# AM13E230x register map
Vendor: Texas Instruments; File version: Revised: 2025-12-26 17:30:06
CPU: CM33 r0p0, little endian, MPU, FPU, 4 interrupt priority bits
Registers are 32-bit, read-write, reset 0x0 unless marked. A register's access mark holds for its fields unless they carry their own. Offsets are from the block's base; [hi:lo] are bit positions; {n}, {i} and the like mark numbered series; 'fields as' and 'values as' point back to an identical list.

## EPI0 — External peripheral interface
Base 0x4001A000
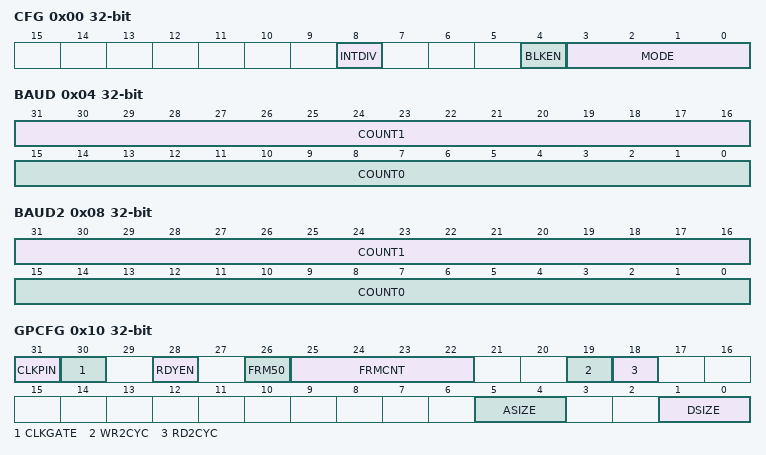
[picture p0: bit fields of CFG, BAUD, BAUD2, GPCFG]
0x00 CFG — EPI Configuration
  [8] INTDIV — Integer Clock Divider Enable
    0=FORMULA (EPIBAUD register values create formula clock divide.); 1=INTEGER (EPIBAUD register values create integer clock divide.)
  [4] BLKEN — Block Enable
    0=DISABLE (The EPI controller is disabled.); 1=ENABLE (The EPI controller is enabled.)
  [3:0] MODE — Mode Select
    0=GP (General Purpose. General-Purpose mode. Control, address, and data pins are configured using the EPIGPCFG and EPIGPCFG2 registers.); 1=SDRAM (SDRAM. Supports SDR SDRAM. Control, address, and data pins are configured using the EPISDRAMCFG register.); 2=HB8 (8-Bit Host-Bus (HB8). Host-bus 8-bit interface (also known as the MCU interface). Control, address, and data pins are configured using the EPIHB8CFG and EPIHB8CFG2 registers.); 3=HB16 (16-Bit Host-Bus (HB16). Host-bus 16-bit interface (standard SRAM). Control, address, and data pins are configured using the EPIHB16CFG and EPIHB16CFG2 registers.)
0x04 BAUD — EPI Main Baud Rate
  [31:16] COUNT1 — Baud Rate Counter 1
  [15:0] COUNT0 — Baud Rate Counter 0
0x08 BAUD2 — EPI Main Baud Rate
  [31:16] COUNT1 — CS3n Baud Rate Counter 1
  [15:0] COUNT0 — CS2n Baud Rate Counter 0
0x10 GPCFG — EPI General-Purpose Configuration
  [31] CLKPIN — Clock Pin
    0=DISABLE (No clock output.); 1=ENABLE (EPI0S31 functions as the EPI clock output.)
  [30] CLKGATE — Clock Gated
    0=FREE_RUN (The EPI clock is free running.); 1=FORCE_LOW (The EPI clock is output only when there is data to write or read (current transaction); otherwise the EPI clock is held low.)
  [28] RDYEN — Ready Enable
    0=NOT_USED (The external peripheral does not drive an iRDY signal and is assumed to be ready always.); 1=ENABLE (The external peripheral drives an iRDY signal into pin EPI0S27.)
  [26] FRM50 — 50/50 Frame
    0=GPCFG_FRAME_PULSE (The FRAME signal is output as a single pulse, and then held low for the count.); 1=GPCFG_FRAME_50_50 (The FRAME signal is output as 50/50 duty cycle using count (see FRMCNT).)
  [25:22] FRMCNT — Frame Count
  [19] WR2CYC — 2-Cycle Writes
    0=ONE (Data is output on the same EPI clock cycle as the address.); 1=TWO (Writes are two EPI clock cycles long, with address on one EPI clock cycle (with the WR strobe asserted) and data written on the following EPI clock cycle (with WR strobe de-asserted). The next address (if any) is in the cycle following.)
  [18] RD2CYC — 2-Cycle Reads
    0=ONE (Data is captured on the EPI clock cycle with READ strobe asserted.); 1=TWO (Reads are two EPI clock cycles, with address on one EPI clock cycle (with the RD strobe asserted) and data captured on the following EPI clock cycle (with the RD strobe de-asserted). The next address (if any) is in the cycle following.)
  [5:4] ASIZE — Address Bus Size
    0=GPCFG_ADDR_SIZE_NONE (No address); 1=GPCFG_ADDR_SIZE_4 (Up to 4 bits wide.); 2=GPCFG_ADDR_SIZE_12 (Up to 12 bits wide. This size cannot be used with 24-bit data.); 3=GPCFG_ADDR_SIZE_20 (Up to 20 bits wide. This size cannot be used with data sizes other than 8.)
  [1:0] DSIZE — Size of Data Bus
    0=GPCFG_BUS_SIZE_8 (8 bits wide (EPI0S0 to EPI0S7)); 1=GPCFG_BUS_SIZE_16 (16 bits wide (EPI0S0 to EPI0S15)); 2=GPCFG_BUS_SIZE_24 (24 bits wide (EPI0S0 to EPI0S23)); 3=GPCFG_BUS_SIZE_32 (32 bits wide (EPI0S0 to EPI0S31)This size may not be used with an EPI clock. This value is normally used for acquisition input and actuator control as well as other general-purpose uses that require 32 bits per direction.)
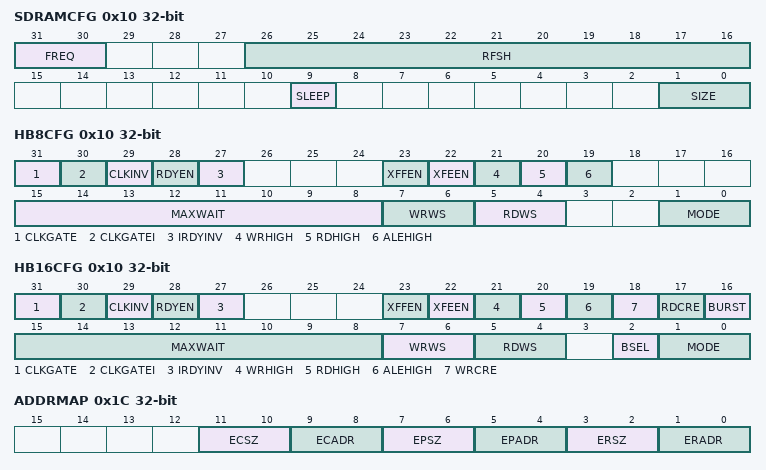
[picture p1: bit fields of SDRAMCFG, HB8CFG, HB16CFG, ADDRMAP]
0x10 SDRAMCFG (alternate view of GPCFG) — EPI SDRAM Configuration
  [31:30] FREQ — EPI Frequency Range.
    0=SDRAMCFG_0_TO_15_MHZ (0 to 15 MHz); 1=SDRAMCFG_15_TO_30_MHZ (15 to 30 MHz); 2=SDRAMCFG_30_TO_50_MHZ (30 to 50 MHz); 3=SDRAMCFG_50_TO_100_MHZ (50 to 100 MHz)
  [26:16] RFSH — Refresh Counter
  [9] SLEEP — Sleep Mode
    0=NONE (No effect.); 1=ON (The SDRAM is put into low power state, but is self-refreshed.)
  [1:0] SIZE — Size of SDRAM
    0=SDRAMCFG_SIZE_64MBITS (64 megabits (8MB)); 1=SDRAMCFG_SIZE_128MBITS (128 megabits (16MB)); 2=SDRAMCFG_SIZE_256MBITS (256 megabits (32MB)); 3=SDRAMCFG_SIZE_512MBITS (512 megabits (64MB))
0x10 HB8CFG (alternate view of GPCFG) — EPI Host-Bus 8 Configuration
  [31] CLKGATE — Clock Gated
    0=FREE_RUN (The EPI clock is free running.); 1=FORCE_LOW (The EPI clock is held low.)
  [30] CLKGATEI — Clock Gated when Idle
    values as GPCFG.CLKGATE
  [29] CLKINV — Invert Output Clock Enable
    0=NORMAL (No effect.); 1=INVERT (Invert EPI clock to ensure the rising edge is centered for outbound signal's setup and hold. Inbound signal is captured on rising edge EPI clock.)
  [28] RDYEN — Input Ready Enable
    0=DISABLE (No effect.); 1=ENABLE (An external ready can be used to control the continuation of the current access. If this bit is set and the iRDY signal (EPIS032) is low, the current access is stalled.)
  [27] IRDYINV — Input Ready Invert
    0=NORMAL (No effect.); 1=INVERT (Invert the polarity of incoming external ready (iRDY signal). If this bit is set and the iRDY signal (EPIS032) is high the current access is stalled.)
  [23] XFFEN — External FIFO FULL Enable
    0=MONITOR_OFF (No effect.); 1=MONITOR (An external FIFO full signal can be used to control write cycles. If this bit is set and the FFULL full signal is high, XFIFO writes are stalled.)
  [22] XFEEN — External FIFO EMPTY Enable
    0=MONITOR_OFF (No effect.); 1=MONITOR (An external FIFO empty signal can be used to control read cycles. If this bit is set and the FEMPTY signal is high, XFIFO reads are stalled.)
  [21] WRHIGH — WRITE Strobe Polarity
    0=LOW (The WRITE strobe for CS0n is WRn (active Low).); 1=HIGH (The WRITE strobe for CS0n is WR (active High).)
  [20] RDHIGH — READ Strobe Polarity
    0=LOW (The READ strobe for CS0n is RDn (active Low).); 1=HIGH (The READ strobe for CS0n is RD (active High).)
  [19] ALEHIGH — ALE Strobe Polarity
    0=LOW (The address latch strobe for CS0n accesses is ALEn (active Low).); 1=HIGH (The address latch strobe for CS0n accesses is ALE (active High).)
  [15:8] MAXWAIT — Maximum Wait
  [7:6] WRWS — Write Wait States
    0=WRN2 (Active WRn is 2 EPI clocks.); 1=WRN4 (Active WRn is 4 EPI clocks.); 2=WRN6 (Active WRn is 6 EPI clocks.); 3=WRN8 (Active WRn is 8 EPI clocks.)
  [5:4] RDWS — Read Wait States
    0=RDN2 (Active RDn is 2 EPI clocks.); 1=RDN4 (Active RDn is 4 EPI clocks.); 2=RDN6 (Active RDn is 6 EPI clocks.); 3=RDN8 (Active RDn is 8 EPI clocks.)
  [1:0] MODE — Host Bus Sub-Mode
    0=ADMUX (ADMUX - AD[7:0]. Data and Address are muxed.); 1=ADNONMUX (ADNONMUX - D[7:0]. Data and address are separate.); 2=CONT_READ (Continuous Read - D[7:0]. This mode is the same as ADNONMUX, but uses address switch for multiple reads instead of OEn strobing.); 3=XFIFO (XFIFO - D[7:0]. This mode adds XFIFO controls with sense of XFIFO full and XFIFO empty. This mode uses no address or ALE. The XFIFO can only be used in asynchronous mode.)
0x10 HB16CFG (alternate view of GPCFG) — EPI Host-Bus 16 Configuration
  [31] CLKGATE — Clock Gated
    values as HB8CFG.CLKGATE
  [30] CLKGATEI — Clock Gated Idle
    values as GPCFG.CLKGATE
  [29] CLKINV — Invert Output Clock Enable
    0=NORMAL (No effect.); 1=INVERT (Invert EPI clock to ensure the rising edge is centered for outbound signals setup and hold. Inbound signal is captured on rising edge EPI clock.)
  [28] RDYEN — Input Ready Enable
    0=DISABLE (No effect.); 1=ENABLE (An external ready (iRDY) can be used to control the continuation of the current access. If this bit is set and the iRDY signal (EPIS032) is low, the current access is stalled.)
  [27] IRDYINV — Input Ready Invert
    0=NORMAL (No effect.); 1=INVERT (Invert polarity of incoming external ready. If this bit is set and the iRDY signal (EPIS032) is high the current access is stalled.)
  [23] XFFEN — External FIFO FULL Enable
    0=MONITOR_OFF (No effect.); 1=MONITOR (An external FIFO full signal can be used to control write cycles. If this bit is set and the FFULL signal is high, XFIFO writes are stalled.)
  [22] XFEEN — External FIFO EMPTY Enable
    values as HB8CFG.XFEEN
  [21] WRHIGH — WRITE Strobe Polarity
    values as HB8CFG.WRHIGH
  [20] RDHIGH — READ Strobe Polarity
    values as HB8CFG.RDHIGH
  [19] ALEHIGH — ALE Strobe Polarity
    0=LOW (The address latch strobe for CS0n is ALEn (active Low).); 1=HIGH (The address latch strobe for CS0n is ALE (active High).)
  [18] WRCRE — PSRAM Configuration Register Write
    0=FORCE_CLEAR (No Action.); 1=TRIGGER (Start CRE write transaction for CS0n.)
  [17] RDCRE — PSRAM Configuration Register Read
    0=FORCE_CLEAR (No Action.); 1=TRIGGER (Start CRE read transaction for CS0n.)
  [16] BURST — Burst Mode
    0=DISABLE (Burst mode is disabled.); 1=ENABLE (Burst mode is enabled for CS0n or single chip access.)
  [15:8] MAXWAIT — Maximum Wait
  [7:6] WRWS — Write Wait States
    values as HB8CFG.WRWS
  [5:4] RDWS — Read Wait States
    values as HB8CFG.RDWS
  [2] BSEL — Byte Select Configuration
    0=NO_BYTE_SELECTS (No Byte SelectsData is read and written as 16 bits.); 1=ENABLE_BYLE_SELECT (Enable Byte SelectsTwo EPI signals function as byte select signals to allow 8-bit transfers. See for details on which EPI signals are used.)
  [1:0] MODE — Host Bus Sub-Mode
    0=ADMUX (ADMUX - AD[15:0]Data and Address are muxed.); 1=ADNONMUX (ADNONMUX - D[15:0]Data and address are separate. This mode is not practical in HB16 mode for normal peripherals because there are generally not enough address bits available.); 2=CONT_READ (Continuous Read - D[15:0]This mode is the same as ADNONMUX, but uses address switch for multiple reads instead of OEn strobing. This mode is not practical in HB16 mode for normal SRAMs because there are generally not enough address bits available.); 3=XFIFO (XFIFO - D[15:0]This mode adds XFIFO controls with sense of XFIFO full and XFIFO empty. This mode uses no address or ALE.Note that the XFIFO can only be used in asynchronous mode.)
0x14 HB8CFG2 — EPI Host-Bus 8 Configuration 2
0x14 HB16CFG2 (alternate view of HB8CFG2) — EPI Host-Bus 16 Configuration 2
0x1C ADDRMAP — EPI Address Map
  [11:10] ECSZ — External Code Size
    0=ADDR_CODE_SIZE_256 (256 bytes; lower address range: 0x00 to 0xFF); 1=ADDR_CODE_SIZE_64K (64 KB; lower address range: 0x0000 to 0xFFFF); 2=ADDR_CODE_SIZE_16M (16 MB; lower address range: 0x000000 to 0xFFFFFF); 3=ADDR_CODE_SIZE_256M (256MB; lower address range: 0x0000000 to 0x0FFFFFFF)
  [9:8] ECADR — External Code Address
    0=NO_MAP (Not mapped); 1=MAP_10000000 (At 0x10000000)
  [7:6] EPSZ — External Peripheral Size
    0=ADDR_PERIPH_SIZE_256 (256 bytes; lower address range: 0x00 to 0xFF); 1=ADDR_PERIPH_SIZE_64K (64 KB; lower address range: 0x0000 to 0xFFFF); 2=ADDR_PERIPH_SIZE_16M (16 MB; lower address range: 0x000000 to 0xFFFFFF); 3=ADDR_PERIPH_SIZE_256M (256 MB; lower address range: 0x0000000 to 0xFFFFFFF)
  [5:4] EPADR — External Peripheral Address
    0=NO_MAP (Not mapped); 1=MAP_60000000 (External Peripheral (EPADR): maps to 0xA0000000 | External RAM (ERADR): same bit value maps to 0x60000000 (not supported on AM13E2x)); 2=MAP_80000000 (External Peripheral (EPADR): maps to 0xC0000000 | External RAM (ERADR): same bit value maps to 0x80000000); 3=DUAL_MAP (Only to be used with Host Bus quad chip select. In quad chip select mode, CS2n maps to 0xA0000000 and CS3n maps to 0xC0000000.)
  [3:2] ERSZ — External RAM Size
    0=ADDR_MEM_SIZE_256 (256 bytes; lower address range: 0x00 to 0xFF); 1=ADDR_MEM_SIZE_64K (64 KB; lower address range: 0x0000 to 0xFFFF); 2=ADDR_MEM_SIZE_16M (16 MB; lower address range: 0x000000 to 0xFFFFFF); 3=ADDR_MEM_SIZE_256M (256 MB; lower address range: 0x0000000 to 0xFFFFFFF)
  [1:0] ERADR — External RAM Address
    0=NO_MAP (Not mapped); 1=MAP_60000000 (At 0x60000000); 2=MAP_80000000 (At 0x80000000); 3=DUAL_MAP (Only to be used with Host Bus quad chip select. In quad chip select mode, CS0n maps to 0x60000000 and CS1n maps to 0x80000000.)
0x20 RSIZE0 reset 0x3 — EPI Read Size 0
  [1:0] SIZE — Current Size
    1=SIZE_8_BIT (Byte (8 bits)); 2=SIZE_16_BIT (Half-word (16 bits)); 3=SIZE_32_BIT (Word (32 bits))
0x24 RADDR0 — EPI Read Address 0
  [31:0] ADDR — Current Address
0x28 RPSTD0 — EPI Non-Blocking Read Data 0
  [12:0] POSTCNT — Post Count
0x30 RSIZE1 reset 0x3 — EPI Read Size 1
  fields as RSIZE0
0x34 RADDR1 — EPI Read Address 1
  [31:0] ADDR — Current Address
0x38 RPSTD1 — EPI Non-Blocking Read Data 1
  [12:0] POSTCNT — Post Count
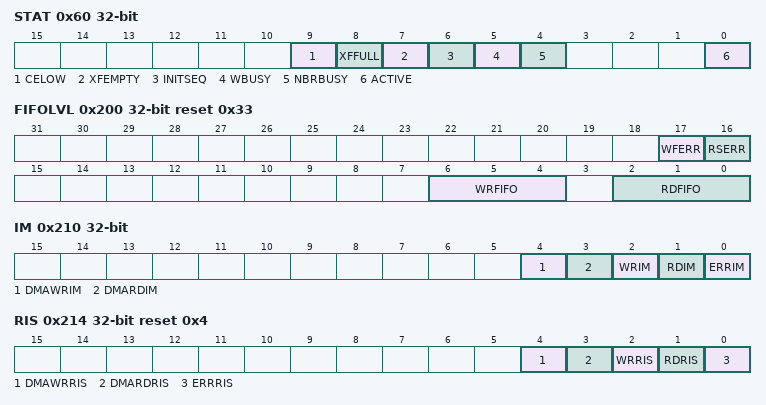
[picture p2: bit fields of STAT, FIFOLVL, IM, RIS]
0x60 STAT — EPI Status
  [9] CELOW — Clock Enable Low
    0=OFF (The external device is not gating the clock.); 1=ON (The external device is gating the clock (iRDY is low). Attempts to read or write in this situation are stalled until the clock is enabled or the counter times out as specified by the MAXWAIT field.)
  [8] XFFULL — External FIFO Full
    0=OKAY (The XFIFO is not signaling as full.); 1=FULL (The XFIFO is signaling as full (the FIFO full signal is high). Attempts to write in this case are stalled until the XFIFO full signal goes low or the counter times out as specified by the MAXWAIT field.)
  [7] XFEMPTY — External FIFO Empty
    0=OKAY (The XFIFO is not signaling as empty.); 1=EMPTY (The XFIFO is signaling as empty (the FIFO empty signal is high). Attempts to read in this case are stalled until the XFIFO empty signal goes low or the counter times out as specified by the MAXWAIT field.)
  [6] INITSEQ — Initialization Sequence
    0=OKAY (The SDRAM interface is not in the wakeup period.); 1=BUSY (The SDRAM interface is running through the wakeup period (greater than 100 microseconds).If an attempt is made to read or write the SDRAM during this period, the access is held off until the wakeup period is complete.)
  [5] WBUSY — Write Busy
    0=FREE (The external interface is not performing a write.); 1=BUSY (The external interface is performing a write.)
  [4] NBRBUSY — Non-Blocking Read Busy
    0=FREE (The external interface is not performing a non-blocking read.); 1=BUSY (The external interface is performing a non-blocking read, or if the non-blocking read is paused due to a write.)
  [0] ACTIVE
    0=STD0 (If NBRBUSY is set, the EPIRPSTD0 register is active.If the NBRBUSY bit is clear, then neither EPIRPSTDx register is active.); 1=STD1 (The EPIRPSTD1 register is active.)
0x6C RFIFOCNT (reset mask 0xFFFFFFF0) — EPI Read FIFO Count
  [3:0] COUNT — FIFO Count.
{0x70+4i} READFIFO{i} (reset mask 0xFFFFFFF) (i=0..7) — EPI Read FIFO {i}
  [31:0] DATA — Reads Data.
0x200 FIFOLVL reset 0x33 — EPI FIFO Level Selects
  [17] WFERR — Write Full Error
    0=DISABLE (The Write Full error interrupt is disabled. Writes are stalled when the WFIFO is full until a space becomes available but an error is not generated. Note that the Cortex-M4 write buffer may hide that stall if no other memory transactions are attempted during that time.); 1=ENABLE (This bit enables the Write Full error interrupt (WTFULL in the EPIEISC register) to be generated when a write is attempted and the WFIFO is full. The write stalls until a WFIFO entry becomes available.)
  [16] RSERR — Read Stall Error
    0=DISABLE (The Read Stalled error interrupt is disabled. Reads behave as normal and are stalled until any preceding writes have completed and the read has returned a result.); 1=ENABLE (This bit enables the Read Stalled error interrupt (RSTALL in the EPIEISC register) to be generated when a read is attempted and the WFIFO is not empty. The read is still stalled during the time the WFIFO drains, but this error notifies the application that this excess delay has occurred.)
  [6:4] WRFIFO — Write FIFO
    0=EMPTY (Interrupt is triggered while WRFIFO is empty. It will be deasserted when not empty. This encoding is optimized for burst of 4 writes.); 2=ENTRIES_2 (Interrupt is triggered until there are only two slots available. Thus, trigger is deasserted when there are two WRFIFO entries present. This configuration is optimized for bursts of 2.); 3=ENTRIES_1 (Interrupt is triggered until there is one WRFIFO entry available. This configuration expects only single writes.); 4=NOT_FULL (Trigger interrupt when WRFIFO is not full, meaning trigger will continue to assert until there are four entries in the WRFIFO.)
  [2:0] RDFIFO — Read FIFO
    1=ENTRIES_1 (Trigger when there are 1 or more entries in the NBRFIFO.); 2=ENTRIES_2 (Trigger when there are 2 or more entries in the NBRFIFO.); 3=ENTRIES_4 (Trigger when there are 4 or more entries in the NBRFIFO.); 4=ENTRIES_6 (Trigger when there are 6 or more entries in the NBRFIFO.); 5=ENTRIES_7 (Trigger when there are 7 or more entries in the NBRFIFO.); 6=ENTRIES_8 (Trigger when there are 8 entries in the NBRFIFO.)
0x204 WFIFOCNT reset 0x4 — EPI Write FIFO Count
  [2:0] WTAV — Available Write Transactions.
0x208 DMATXCNT — EPI DMA Transmit Count
  [15:0] TXCNT — DMA Count.
0x210 IM — EPI Interrupt Mask
  [4] DMAWRIM — Write uDMA Interrupt Mask
    0=DMAWR_MASK (DMAWRRIS in the EPIRIS register is masked and does not cause an interrupt.); 1=DMAWR (DMAWRRIS in the EPIRIS register is not masked and can trigger an interrupt to the interrupt controller.)
  [3] DMARDIM — Read uDMA Interrupt Mask
    0=DMARD_MASK (DMARDRIS in the EPIRIS register is masked and does not cause an interrupt.); 1=DMARD (DMARDRIS in the EPIRIS register is not masked and can trigger an interrupt to the interrupt controller.)
  [2] WRIM — Write FIFO Empty Interrupt Mask
    0=WR_MASK (WRRIS in the EPIRIS register is masked and does not cause an interrupt.); 1=WR (WRRIS in the EPIRIS register is not masked and can trigger an interrupt to the interrupt controller.)
  [1] RDIM — Read FIFO Full Interrupt Mask
    0=RD_MASK (RDRIS in the EPIRIS register is masked and does not cause an interrupt.); 1=RD (RDRIS in the EPIRIS register is not masked and can trigger an interrupt to the interrupt controller.)
  [0] ERRIM — Error Interrupt Mask
    0=ERR_MASK (ERRIS in the EPIRIS register is masked and does not cause an interrupt.); 1=ERR (ERRIS in the EPIRIS register is not masked and can trigger an interrupt to the interrupt controller.)
0x214 RIS reset 0x4 — EPI Raw Interrupt Status
  [4] DMAWRRIS — Write uDMA Raw Interrupt Status
    0=DMAWR_CLR (The write uDMA has not completed.); 1=DMAWR (The write uDMA has completed.)
  [3] DMARDRIS — Read uDMA Raw Interrupt Status
    0=DMARD_CLR (The read uDMA has not completed.); 1=DMARD (The read uDMA has completed.)
  [2] WRRIS — Write Raw Interrupt Status
    0=WR_CLR (The number of available entries in the WFIFO is above the range specified by the WRFIFO field in the EPIFIFOLVL register.); 1=WR (The number of available entries in the WFIFO is within the trigger range specified by the WRFIFO field in the EPIFIFOLVL register.)
  [1] RDRIS — Read Raw Interrupt Status
    0=RD_CLR (The number of valid entries in the NBRFIFO is below the trigger range specified by the RDFIFO field in the EPIFIFOLVL register.); 1=RD (The number of valid entries in the NBRFIFO is in the trigger range specified by the RDFIFO field in the EPIFIFOLVL register.)
  [0] ERRRIS — Error Raw Interrupt Stat Error Raw Interrupt Status
    0=ERR_CLR (An error has not occurred.); 1=ERR (A WFIFO Full, a Read Stalled, or a Timeout error has occurred. To determine which error occurred, read the status of the EPI Error Interrupt Status and Clear (EPIEISC) register. This bit is cleared by writing a 1 to the bit in the EPIEISC register that caused the interrupt.)
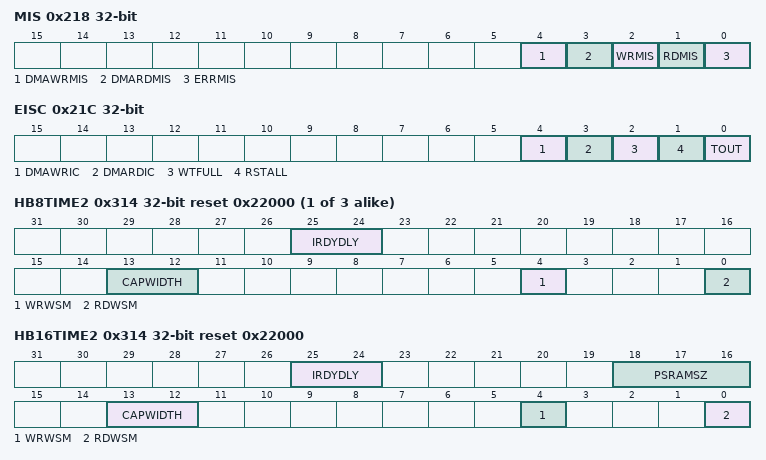
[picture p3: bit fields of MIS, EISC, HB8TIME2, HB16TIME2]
0x218 MIS — EPI Masked Interrupt Status
  [4] DMAWRMIS — Write uDMA Masked Interrupt Status.
    0=DMAWR_CLR (The write uDMA has not completed or the interrupt is masked.); 1=DMAWR (The write uDMA has completed and the DMAWRIM bit in the EPIIM register is set, triggering an interrupt to the interrupt controller.)
  [3] DMARDMIS — Read uDMA Masked Interrupt Status.
    0=DMARD_CLR (The read uDMA has not completed or the interrupt is masked.); 1=DMARD (The read uDMA has completed and the DMAWRIM bit in the EPIIM register is set, triggering an interrupt to the interrupt controller.)
  [2] WRMIS — Write Masked Interrupt Status
    0=WR_CLR (The number of available entries in the WFIFO is above the range specified by the trigger level or the interrupt is masked.); 1=WR (The number of available entries in the WFIFO is within the range specified by the trigger level (the WRFIFO field in the EPIFIFOLVL register) and the WRIM bit in the EPIIM register is set, triggering an interrupt to the interrupt controller.)
  [1] RDMIS — Read Masked Interrupt Status
    0=RD_CLR (The number of valid entries in the NBRFIFO is below the range specified by the trigger level or the interrupt is masked.); 1=RD (The number of valid entries in the NBRFIFO is within the range specified by the trigger level (the RDFIFO field in the EPIFIFOLVL register) and the RDIM bit in the EPIIM register is set, triggering an interrupt to the interrupt controller.)
  [0] ERRMIS — Error Masked Interrupt Status
    0=ERR_CLR (An error has not occurred or the interrupt is masked.); 1=ERR (A WFIFO Full, a Read Stalled, or a Timeout error has occurred and the ERIM bit in the EPIIM register is set, triggering an interrupt to the interrupt controller.)
0x21C EISC — EPI Error and Interrupt Status and Clear
  [4] DMAWRIC — Write uDMA Interrupt Clear.
  [3] DMARDIC — Read uDMA Interrupt Clear.
  [2] WTFULL — Write FIFO Full Error.
    0=WTFULL_CLEAR (The WFERR bit is not enabled or no writes are stalled.); 1=WTFULL (The WFERR bit is enabled and a write is stalled due to the WFIFO being full.)
  [1] RSTALL — Read Stalled Error.
    0=RSTALL_CLEAR (The RSERR bit is not enabled or no pending reads are stalled.); 1=RSTALL (The RSERR bit is enabled and a pending read is stalled due to writes in the WFIFO.)
  [0] TOUT — Timeout Error.
    0=TOUT_CLEAR (No timeout error has occurred.); 1=TOUT (A timeout error has occurred.)
0x308 HB8CFG3 reset 0x80000 — EPI Host-Bus 8 Configuration 3
0x308 HB16CFG3 reset 0x80000 (alternate view of HB8CFG3) — EPI Host-Bus 16 Configuration 3
0x30C HB8CFG4 reset 0x80000 — EPI Host-Bus 8 Configuration 4
0x30C HB16CFG4 reset 0x80000 (alternate view of HB8CFG4) — EPI Host-Bus 16 Configuration 4
0x310 HB8TIME reset 0x22000 — EPI Host-Bus 8 Timing Extension
0x310 HB16TIME reset 0x22000 (alternate view of HB8TIME) — EPI Host-Bus 16 Timing Extension
{0x30C+4i} HB8TIME{i} reset 0x22000 (i=2..4) — EPI Host-Bus 8 Timing Extension
  [25:24] IRDYDLY — CS{i-1}n Input Ready Delay
    1=CLK_1 (Stall begins one EPI clocks past iRDY low being sampled on the rising edge of EPIO clock.); 2=CLK_2 (Stall begins two EPI clocks past iRDY low being sampled on the rising edge of EPIO clock.); 3=CLK_3 (Stall begins three EPI clocks past iRDY low being sampled on the rising edge of EPIO clock.)
  [13:12] CAPWIDTH — CS{i-1}n Inter-transfer Capture Width
    1=CLK_1 (1 EPI clock.); 2=CLK_2 (2 EPI clock.)
  [4] WRWSM — CS{i-1}n Write Wait State Minus One
    0=UNCHANGED (No change in the number of wait state clock cycles programmed in the in WRWS field in EPIHB8CFG register.); 1=MINUS_ONE (Wait state value is now (WRWS - 1) where the WRWS field is programmed in EPIHB8CFG.)
  [0] RDWSM — CS{i-1}n Read Wait State Minus One
    0=UNCHANGED (No change in the number of wait state clock cycles programmed in the RDWS field of EPIHB8CFG.); 1=MINUS_ONE (Wait state value is now (RDWS - 1) where the RDWS field is programmed in EPIHB8CFG.)
0x314 HB16TIME2 reset 0x22000 (alternate view of HB8TIME2) — EPI Host-Bus 16 Timing Extension
  [25:24] IRDYDLY — CS1n Input Ready Delay
    values as HB8TIME2.IRDYDLY
  [18:16] PSRAMSZ — PSRAM Row Size
    0=NO_LIMIT (No row size limitation); 1=BYTES_128 (128 B); 2=BYTES_256 (256 B); 3=BYTES_512 (512 B); 4=BYTES_1024 (1024 B); 5=BYTES_2048 (2048 B); 6=BYTES_4096 (4096 B); 7=BYTES_8192 (8192 B)
  [13:12] CAPWIDTH — CS1n Inter-transfer Capture Width
    1=CLK_1 (1 EPI clock.); 2=CLK_2 (2 EPI clock.)
  [4] WRWSM — CS1n Write Wait State Minus One
    0=UNCHANGED (No change in the number of wait state clock cycles programmed in the in WRWS field in EPIHB16CFG register.); 1=MINUS_ONE (Wait state value is now (WRWS - 1) where the WRWS field is programmed in EPIHB16CFG.)
  [0] RDWSM — CS1n Read Wait State Minus One
    0=UNCHANGED (No change in the number of wait state clock cycles programmed in the RDWS field of EPIHB16CFG.); 1=MINUS_ONE (Wait state value is now (RDWS - 1) where the RDWS field is programmed in EPIHB16CFG.)
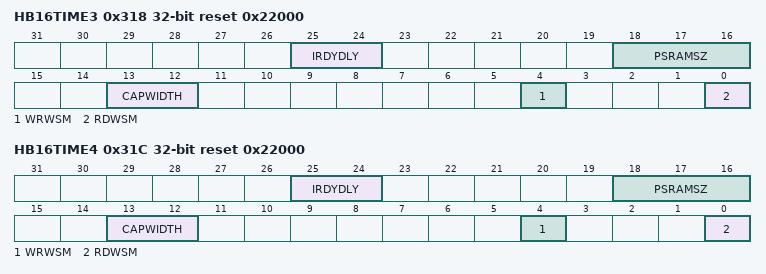
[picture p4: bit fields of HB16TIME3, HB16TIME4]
0x318 HB16TIME3 reset 0x22000 (alternate view of HB8TIME3) — EPI Host-Bus 16 Timing Extension
  [25:24] IRDYDLY — CS2n Input Ready Delay
    values as HB8TIME2.IRDYDLY
  [18:16] PSRAMSZ — PSRAM Row Size
    values as HB16TIME2.PSRAMSZ
  [13:12] CAPWIDTH — CS2n Inter-transfer Capture Width
    1=CLK_1 (1 EPI clock.); 2=CLK_2 (2 EPI clock.)
  [4] WRWSM — CS2n Write Wait State Minus One
    values as HB16TIME2.WRWSM
  [0] RDWSM — CS2n Read Wait State Minus One
    values as HB16TIME2.RDWSM
0x31C HB16TIME4 reset 0x22000 (alternate view of HB8TIME4) — EPI Host-Bus 16 Timing Extension
  [25:24] IRDYDLY — CS3n Input Ready Delay
    values as HB8TIME2.IRDYDLY
  [18:16] PSRAMSZ — PSRAM Row Size.
    values as HB16TIME2.PSRAMSZ
  [13:12] CAPWIDTH — CS3n Inter-transfer Capture Width.
    1=CLK_1 (1 EPI clock); 2=CLK_2 (2 EPI clock)
  [4] WRWSM — CS3n Write Wait State Minus One.
    values as HB16TIME2.WRWSM
  [0] RDWSM — CS3n Read Wait State Minus One.
    values as HB16TIME2.RDWSM
0x360 HBPSRAM — EPI Host-Bus PSRAM
  [20:0] CR — PSRAM Config Register.
